# H5 register map
Vendor: Allwinner; Series: H5; File version: 0.1
CPU: 0, little endian, MPU, no FPU, 0 interrupt priority bits
Registers are 32-bit, read-write, reset 0x0 unless marked. A register's access mark holds for its fields unless they carry their own. Offsets are from the block's base; [hi:lo] are bit positions; 'fields as' and 'values as' point back to an identical list.

## TIMER
Base 0x01C20C00
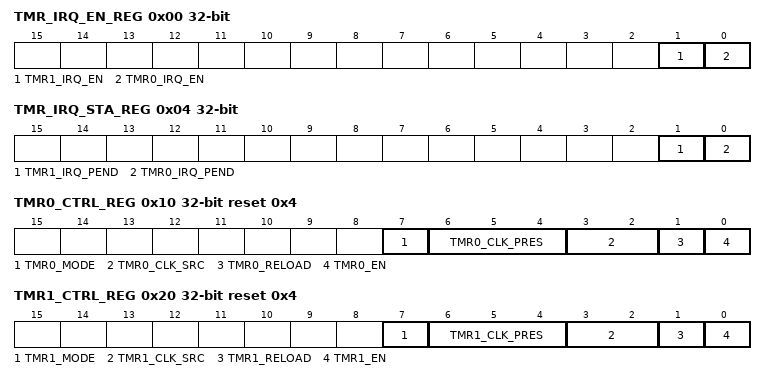
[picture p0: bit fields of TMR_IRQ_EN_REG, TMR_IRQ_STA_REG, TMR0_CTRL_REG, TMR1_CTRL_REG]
0x00 TMR_IRQ_EN_REG — Timer IRQ Enable Register
  [1] TMR1_IRQ_EN write-1-sets — Timer 1 Interrupt Enable. 0: No effect. 1: Timer 1 interval value reached interrupt enable.
    0=No_effect; 1=Timer 1 interval value reached interrupt enable
  [0] TMR0_IRQ_EN write-1-sets — Timer 0 Interrupt Enable. 0: No effect. 1: Timer 0 interval value reached interrupt enable.
    0=No_effect; 1=Timer 0 interval value reached interrupt enable
0x04 TMR_IRQ_STA_REG — Timer Status Register
  [1] TMR1_IRQ_PEND write-1-clears — Timer 1 IRQ Pending. Setting 1 to the bit will clear it. 0: No effect. 1: Pending, timer 1 interval value is reached.
    0=No_effect; 1=Pending, timer 1 interval value is reached
  [0] TMR0_IRQ_PEND write-1-clears — Timer 0 IRQ Pending. Setting 1 to the bit will clear it. 0: No effect. 1: Pending, timer 0 interval value is reached.
    0=No_effect; 1=Pending, timer 0 interval value is reached
0x10 TMR0_CTRL_REG reset 0x4 — Timer 0 Control Register
  [7] TMR0_MODE — Timer 0 mode. 0: Continuous mode. When interval value reached, the timer will not disable automatically. 1: Single mode. When interval value reached, the timer will disable automatically.
    0=Continuous mode. When interval value reached, the timer will not disable automatically.; 1=Single mode. When interval value reached, the timer will disable automatically.
  [6:4] TMR0_CLK_PRES — Select the pre-scale of timer 0 clock source. 000: /1 001: /2 010: /4 011: /8 100: /16 101: /32 110: /64 111: /128
    0=_slash_1 (/1); 1=_slash_2 (/2); 2=_slash_4 (/4); 3=_slash_8 (/8); 4=_slash_16 (/16); 5=_slash_32 (/32); 6=_slash_64 (/64); 7=_slash_128 (/128)
  [3:2] TMR0_CLK_SRC — Timer 0 Clock Source. 00: Internal OSC / N 01: OSC24M. 10: / 11: / Internal OSC / N is about 32KHz.
    0=Internal OSC / N; 1=OSC24M; 3=_slash_ (/ Internal OSC / N is about 32KHz.)
  [1] TMR0_RELOAD write-1-sets — Timer 0 Reload. 0: No effect 1: Reload timer 0 Interval value. After the bit is set, it can not be written again before it is cleared automatically.
    0=No_effect; 1=Reload timer 0 Interval value. After the bit is set, it can not be written again before it is cleared automatically.
  [0] TMR0_EN — Timer 0 Enable. 0: Stop/Pause 1: Start. When the timer is started, it will reload the interval value to internal register, and the current counter will count from interval value to 0. If the current counter does not reach the zero, the TMR0_EN bit is set to , the u e t alue ou te ill pause. At least ait fo les, the TMR0_EN bit can be set to 1. In timer pause state, Timer 0 Interval Value Register can be modified. If the timer is started again, and the software hope Timer 0 Current Value Register to down-count from the new interval value, the Timer 0 Reload bit and the Timer 0 Enable bit should be set to 1 at the same time.
    0=Stop_slash_Pause (Stop/Pause); 1=Start. When the timer is started, it will reload the interval value to internal register, and the current counter will count from interval value to 0. If the current counter does not reach the zero, the TMR0_EN bit is set to , the u e t alue ou te ill pause. At least ait fo les, the TMR0_EN bit can be set to 1. In timer pause state, Timer 0 Interval Value Register can be modified. If the timer is started again, and the software hope Timer 0 Current Value Register to down-count from the new interval value, the Timer 0 Reload bit and the Timer 0 Enable bit should be set to 1 at the same time.
0x14 TMR0_INTV_VALUE_REG — Timer 0 Interval Value Register
  [31:0] TMR0_INTV_VALUE — Timer 0 Interval Value.
0x18 TMR0_CUR_VALUE_REG — Timer 0 Current Value Register
  [31:0] TMR0_CUR_VALUE — Timer 0 Current Value.
0x20 TMR1_CTRL_REG reset 0x4 — Timer 1 Control Register
  [7] TMR1_MODE — Timer 1 mode. 0: Continuous mode. When interval value reached, the timer will not disable automatically. 1: Single mode. When interval value reached, the timer will disable automatically.
    values as TMR0_CTRL_REG.TMR0_MODE
  [6:4] TMR1_CLK_PRES — Select the pre-scale of timer 1 clock source. 000: /1 001: /2 010: /4 011: /8 100: /16 101: /32 110: /64 111: /128
    values as TMR0_CTRL_REG.TMR0_CLK_PRES
  [3:2] TMR1_CLK_SRC — 00: Internal OSC / N 01: OSC24M. 10: / 11: /. Internal OSC / N is about 32KHz.
    0=Internal OSC / N; 1=OSC24M; 3=_slash_ (/. Internal OSC / N is about 32KHz.)
  [1] TMR1_RELOAD write-1-sets — Timer 1 Reload. 0: No effect 1: Reload timer 1 Interval value. Afte the it is set, it a ot e itte agai efo e it s lea ed automatically.
    0=No_effect; 1=Reload timer 1 Interval value. Afte the it is set, it a ot e itte agai efo e it s lea ed automatically.
  [0] TMR1_EN — Timer 1 Enable. 0: Stop/Pause 1: Start. If the timer is started, it will reload the interval value to internal register, and the current counter will count from interval value to 0. If the current counter does not reach the zero, the TMR1_EN it is set to , the current value counter will pause. At least wait for 2 cycles, the TMR1_EN bit can be set to 1. In timer pause state, Timer 1 Interval Value Register can be modified. If the timer is started again, and the software hope Timer 1 Current Value Register to down-count from the new interval value, the Timer 1 Reload bit and the Timer 1 Enable bit should be set to 1 at the same time.
    0=Stop_slash_Pause (Stop/Pause); 1=Start. If the timer is started, it will reload the interval value to internal register, and the current counter will count from interval value to 0. If the current counter does not reach the zero, the TMR1_EN it is set to , the current value counter will pause. At least wait for 2 cycles, the TMR1_EN bit can be set to 1. In timer pause state, Timer 1 Interval Value Register can be modified. If the timer is started again, and the software hope Timer 1 Current Value Register to down-count from the new interval value, the Timer 1 Reload bit and the Timer 1 Enable bit should be set to 1 at the same time.
0x24 TMR1_INTV_VALUE_REG — Timer 1 Interval Value Register
  [31:0] TMR1_INTV_VALUE — Timer 1 Interval Value.
0x28 TMR1_CUR_VALUE_REG — Timer 1 Current Value Register
  [31:0] TMR1_CUR_VALUE — Timer 1 Current Value.
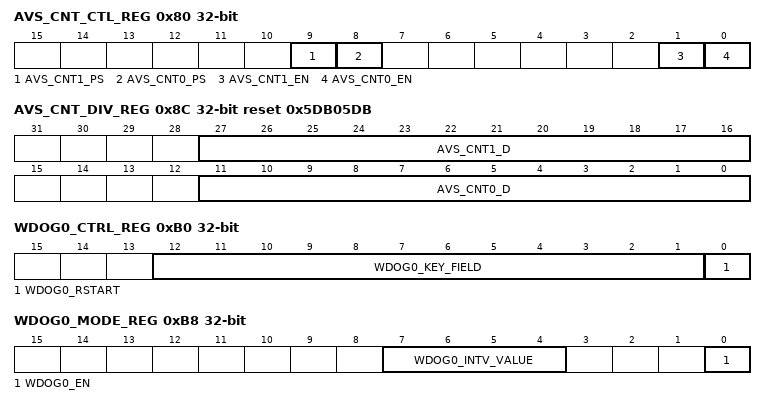
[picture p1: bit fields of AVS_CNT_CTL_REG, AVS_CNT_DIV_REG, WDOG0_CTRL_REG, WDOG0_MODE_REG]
0x80 AVS_CNT_CTL_REG — AVS Control Register
  [9] AVS_CNT1_PS — Audio/Video Sync Counter 1 Pause Control 0: Not pause 1: Pause Counter 1.
    0=Not_pause; 1=Pause Counter 1
  [8] AVS_CNT0_PS — Audio/Video Sync Counter 0 Pause Control 0: Not pause 1: Pause Counter 0.
    0=Not_pause; 1=Pause Counter 0
  [1] AVS_CNT1_EN — Audio/Video Sync Counter 1 Enable/ Disable. The counter source is OSC24M. 0: Disable 1: Enable.
    0=Disable; 1=Enable
  [0] AVS_CNT0_EN — Audio/Video Sync Counter 1 Enable/ Disable. The counter source is OSC24M. 0: Disable 1: Enable.
    0=Disable; 1=Enable
0x84 AVS_CNT0_REG — AVS Counter 0 Register
  [31:0] AVS_CNT0 — Counter 0 for Audio/ Video Sync Application The high 32 bits of the internal 33 bits counter register. The initial value of the internal 33 bits counter register can be set by software. The LSB bit of the 33 bits counter register should be zero when the initial value is updated. It will count from the initial value. The initial value can be updated at any time. It can also be paused by setting AVS_CNT0_PS to . Whe it is paused, the counter will not increase.
0x88 AVS_CNT1_REG — AVS Counter 1 Register
  [31:0] AVS_CNT1 — Counter 1 for Audio/ Video Sync Application The high 32 bits of the internal 33 bits counter register. The initial value of the internal 33 bits counter register can be set by software. The LSB bit of the 33 bits counter register should be zero when the initial value is updated. It will count from the initial value. The initial value can be updated at any time. It can also be paused by setting AVS_CNT1_PS to . Whe it is paused, the counter will not increase.
0x8C AVS_CNT_DIV_REG reset 0x5DB05DB — AVS Divisor Register
  [27:16] AVS_CNT1_D — Divisor N for AVS Counter 1 AVS CN1 CLK=24MHz/Divisor_N1. Divisor N1 = Bit [27:16] + 1. The number N is from 1 to 0x7ff. The zero value is reserved. The internal 33 bits counter engine will maintain another 12 bits counter. The 12 bits counter is used for counting the cycle number of one 24MHz clock. When the 12 bits counter reaches (>= N) the divisor value, the internal 33 bits counter register will increase 1 and the 12 bits counter will reset to zero and restart again.
  [11:0] AVS_CNT0_D — Divisor N for AVS Counter 0 AVS CN0 CLK=24MHz/Divisor_N0. Divisor N0 = Bit [11:0] + 1 The number N is from 1 to 0x7ff. The zero value is reserved. The internal 33 bits counter engine will maintain another 12 bits counter. The 12 bits counter is used for counting the cycle number of one 24MHz clock. When the 12 bits counter reaches (>= N) the divisor value, the internal 33 bits counter register will increase 1 and the 12 bits counter will reset to zero and restart again.
0xA0 WDOG0_IRQ_EN_REG — Watchdog 0 IRQ Enable Register
  [0] WDOG0_IRQ_EN — Watchdog0 Interrupt Enable. 0: No effect. 1: Watchdog0 interrupt enable.
    0=No_effect; 1=Watchdog0 interrupt enable
0xA4 WDOG0_IRQ_STA_REG — Watchdog 0 Status Register
  [0] WDOG0_IRQ_PEND write-1-clears — Watchdog0 n IRQ Pending. Setting 1 to the bit will clear it. 0: No effect. 1: Pending. Watchdog0 interval value is reached.
    0=No_effect; 1=Pending. Watchdog0 interval value is reached.
0xB0 WDOG0_CTRL_REG — Watchdog 0 Control Register
  [12:1] WDOG0_KEY_FIELD — Watchdog0 Key Field. Should be written at value 0xA57. Writing any other value in this field aborts the write operation.
  [0] WDOG0_RSTART write-1-sets — Watchdog0 Restart. 0: No effect. 1: Restart watchdog0.
    0=No_effect; 1=Restart watchdog0
0xB4 WDOG0_CFG_REG reset 0x1 — Watchdog 0 Configuration Register
  [1:0] WDOG0_CONFIG — Watchdog0 generates a reset signal 00: / 01: To whole system 10: Only interrupt 11: /
    1=To whole system; 2=Only_interrupt
0xB8 WDOG0_MODE_REG — Watchdog 0 Mode Register
  [7:4] WDOG0_INTV_VALUE — Watchdog0 Interval Value Watchdog0 clock source is OSC24M / 750 . If the clock source is turned off, Watchdog 0 will not work. 0000: 16000 cycles (0.5s) 0001: 32000 cycles (1s) 0010: 64000 cycles (2s) 0011: 96000 cycles (3s) 0100: 128000 cycles (4s) 0101: 160000 cycles (5s) 0110: 192000 cycles (6s) 0111: 256000 cycles (8s) 1000: 320000 cycles (10s) 1001: 384000 cycles (12s) 1010: 448000 cycles (14s) 1011: 512000 cycles (16s) others: /
    0=16000 cycles (0.5s); 1=32000 cycles (1s); 2=64000 cycles (2s); 3=96000 cycles (3s); 4=128000 cycles (4s); 5=160000 cycles (5s); 6=192000 cycles (6s); 7=256000 cycles (8s); 8=320000 cycles (10s); 9=384000 cycles (12s); 10=448000 cycles (14s); 11=512000 cycles (16s) others: /
  [0] WDOG0_EN write-1-sets — Watchdog0 Enable. 0: No effect 1: Enable watchdog0.
    0=No_effect; 1=Enable watchdog0
